# CY8C5888LTI_LP097 register map
File version: 0.1
CY8C58LP
Registers are 8-bit, read-write, no defined reset value unless marked. A register's access mark holds for its fields unless they carry their own. Offsets are from the block's base; lines under a group give offsets from that group; [hi:lo] are bit positions; {n}, {i} and the like mark numbered series; 'fields as' and 'values as' point back to an identical list; <NAME> marks a mode.

## Memory map
0x00000000 Timer_Reset
0x00000000 RTC
0x00000000 Buzzer_PWM
0x00000000 Timer_R2
0x00000000 Timer_L2
0x00000000 Timer_IR
0x00000000 StatisticsCounter
0x00000000 UART_2 — UART
0x00000000 Timer_L3
0x00000000 Timer_R1
0x00000000 Timer_R3
0x00000000 PWM
0x00000000 UART_1 — UART
0x00000000 I2C
0x00000000 ADC_Battery — SAR ADC
0x00000000 Timer
0x00000000 Timer_L1

## Timer_Reset
Base 0x00000000
0x40006473 Timer_Reset_CONTROL_REG

## RTC
Base 0x00000000
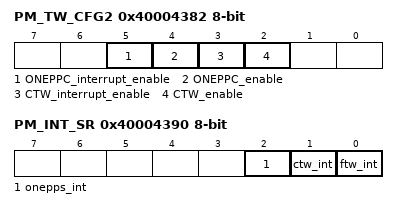
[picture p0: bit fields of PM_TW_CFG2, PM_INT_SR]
0x40004382 PM_TW_CFG2 — Power timers enable and interrupt enable configuration register
  [5] ONEPPC_interrupt_enable — When set and one pulse-per-second is enabled, an interrupt is issued when the pulse occurs
    1=Enabled (The ONEPPC interrupt is issued. Only if ONEPPC is enabled.); 0=Disabled (No ONEPPC interrupt is issued.)
  [4] ONEPPC_enable
    1=Enabled (The ONEPPC is enabled.); 0=Disabled (The ONEPPC is disabled.)
  [3] CTW_interrupt_enable — An interrupt issue when the CTW reaches the selected interval
    1=Enabled (The CTW interrupt is issued. Only if CTW is enabled.); 0=Disabled (No CTW interrupt is issued.)
  [2] CTW_enable
    1=Enabled (The CTW is enabled.); 0=Disabled (The CTW is disabled.)
0x40004390 PM_INT_SR — Power Manager Interrupt Status Register
  [2] onepps_int — When set, a onepps event has occured.
  [1] ctw_int — When set, a limited active ready event has occured
  [0] ftw_int — When set, a fast timewheel event has occured

## Buzzer_PWM
Base 0x00000000
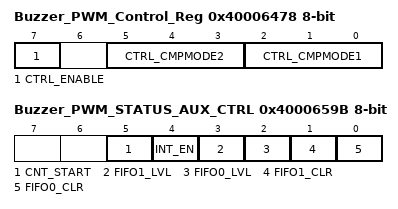
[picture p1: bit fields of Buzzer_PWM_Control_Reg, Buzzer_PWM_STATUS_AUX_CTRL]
0x40006478 Buzzer_PWM_Control_Reg — UDB Control Register - Assigned Control Register Value
  [7] CTRL_ENABLE — Enable the PWM
  [5:3] CTRL_CMPMODE2 — Compare mode 2
  [2:0] CTRL_CMPMODE1 — Compare mode 1
0x4000652B Buzzer_PWM_COMPARE_Reg_ — UDB.D0 - Assigned Compare Value
0x4000659B Buzzer_PWM_STATUS_AUX_CTRL — UDB Auxilliary Control Register
  [5] CNT_START — FIFO0 clear
    0=E_CNT_START0 (Disable counter); 1=E_CNT_START1 (Enable counter)
  [4] INT_EN
    0=E_INT_EN0 (Interrupt disabled); 1=E_INT_EN1 (Interrupt enabled)
  [3] FIFO1_LVL — FIFO level
    0=E_FIFO_LVL_0 (FIFO LVL: input mode: FIFO not full; output mode: FIFO not empty); 1=E_FIFO_LVL_1 (FIFO LVL: input mode: FIFO at least 1/2 empty; output mode: FIFO at least 1/2 full)
  [2] FIFO0_LVL — FIFO level
    values as FIFO1_LVL
  [1] FIFO1_CLR — FIFO1 clear
    0=E_FIFO_CLR_0 (Normal FIFO operation); 1=E_FIFO_CLR_1 (Clear FIFO state)
  [0] FIFO0_CLR — FIFO0 clear
    values as FIFO1_CLR

## Timer_R2
Base 0x00000000
0x4000640E Timer_R2_COUNTER 16-bit — UDB.A0 - Current Down Counter Value
0x4000642E Timer_R2_PERIOD 16-bit — UDB.D0 - Assigned Period
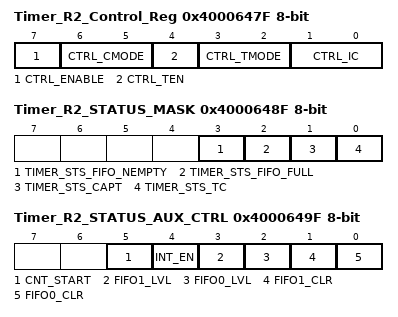
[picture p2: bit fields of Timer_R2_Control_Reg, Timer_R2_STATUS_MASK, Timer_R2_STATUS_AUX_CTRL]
0x4000647F Timer_R2_Control_Reg — UDB Control Register - Assigned Control Register Value
  [7] CTRL_ENABLE — Enable the Timer
  [6:5] CTRL_CMODE — Capture Mode
  [4] CTRL_TEN — Trigger Enable Bit
  [3:2] CTRL_TMODE — Trigger Mode
  [1:0] CTRL_IC — Interrupt Count
0x4000648F Timer_R2_STATUS_MASK — UDB Status bits Interrupt Mask Enable Register
  [3] TIMER_STS_FIFO_NEMPTY ro — FIFO Empty status
  [2] TIMER_STS_FIFO_FULL ro — FIFO Full Status
  [1] TIMER_STS_CAPT ro — Enables the Interrupt on Capture
  [0] TIMER_STS_TC ro — Enables the Interrupt on TC
0x4000649F Timer_R2_STATUS_AUX_CTRL — UDB Auxilliary Control Register
  [5] CNT_START — FIFO0 clear
    0=E_CNT_START0 (Disable counter); 1=E_CNT_START1 (Enable counter)
  [4] INT_EN
    0=E_INT_EN0 (Interrupt disabled); 1=E_INT_EN1 (Interrupt enabled)
  [3] FIFO1_LVL — FIFO level
    0=E_FIFO_LVL_0 (FIFO LVL: input mode: FIFO not full; output mode: FIFO not empty); 1=E_FIFO_LVL_1 (FIFO LVL: input mode: FIFO at least 1/2 empty; output mode: FIFO at least 1/2 full)
  [2] FIFO0_LVL — FIFO level
    values as FIFO1_LVL
  [1] FIFO1_CLR — FIFO1 clear
    0=E_FIFO_CLR_0 (Normal FIFO operation); 1=E_FIFO_CLR_1 (Clear FIFO state)
  [0] FIFO0_CLR — FIFO0 clear
    values as FIFO1_CLR
